# a34m42x register map
Vendor: ABOV Semiconductor Co., Ltd.; File version: 1.0
CPU: CM4 r0p1, little endian, MPU, FPU, VTOR, 4 interrupt priority bits
Registers are 32-bit, read-write, reset 0x0 unless marked. A register's access mark holds for its fields unless they carry their own. Offsets are from the block's base; [hi:lo] are bit positions; {n}, {i} and the like mark numbered series.

## FRT — Free Run Timer
Base 0x50000600
Same registers: FRT0 0x40000600, FRT1 0x40000700
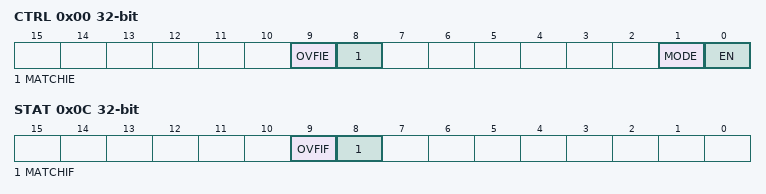
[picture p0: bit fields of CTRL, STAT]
0x00 CTRL — FRT n Control Register
  [9] OVFIE — Over Flow Interrupt Enable bit
    0=Disable (Interrupt Disable); 1=Enable (Interrupt Enable)
  [8] MATCHIE — Match Interrupt Enable Bit
    0=Disable (Interrupt Disable); 1=Enable (Interrupt Enable)
  [1] MODE — FRT Mode Selection Bit
    0=Free-Run_Timer; 1=Match_Timer
  [0] EN — FRT Enable Bit
    0=Disable (FRT Disable); 1=Enable (FRT Enable)
0x04 MCNT reset 0xFFFFFFFF — FRT n Match Counter Register
  [31:0] MCNT — Match Counter Bit
0x08 CNT — FRT n Counter Register
  [31:0] CNT — Counter Bit *only write '0x0'
0x0C STAT — FRT n Status Register
  [9] OVFIF — Overflow Interrupt Flag
  [8] MATCHIF — Match Interrupt Flag

## UART — Universal Asynchronous Receiver/Transmitter
Base 0x50008000
Same registers: UART0 0x40008000, UART1 0x40008100, UART2 0x40008200, UART3 0x40008300, UART4 0x40008400, UART5 0x40008500
0x00 RBR ro — UARTn Receive Data Buffer Register
  [7:0] RBR — Receive buffer
0x00 THR wo — UARTn Transmit Data Hold Register
  [7:0] THR — Transmit buffer
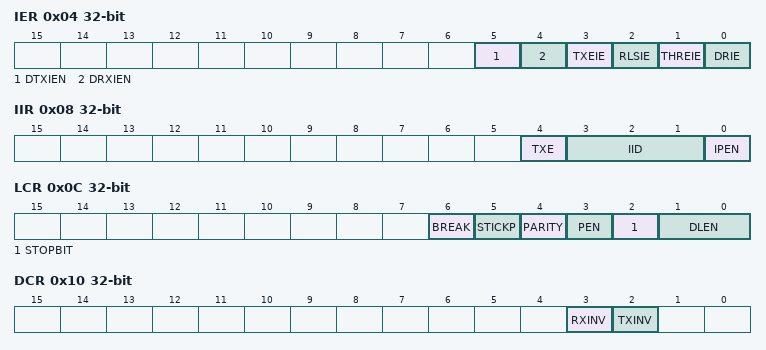
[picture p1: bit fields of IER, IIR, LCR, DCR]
0x04 IER — UARTn Interrupt Enable Register
  [5] DTXIEN — DMA Transmitter complete interrupt allow
  [4] DRXIEN — DMA Receiver over Interrupt allow
  [3] TXEIE — Transmit Empty Interrupt Enable bit
  [2] RLSIE — Receiver Line Status Interrupt Enable bit
  [1] THREIE — Transmit Holding Register Empty Interrupt Enable bit
  [0] DRIE — Data Receive Interrupt Enable bit
0x08 IIR ro — UARTn Interrupt ID Register
  [4] TXE — Transmit Complete Interrupt Source ID bit
  [3:1] IID — UARTn Interrupt ID bits. Note: The UARTn supports 3-priority interrupt generation and the interrupt source ID register shows one interrupt source which has highest priority among pending interrupts. The priority is defined as below. - Receive line status interrupt - Receive data ready interrupt and Character timeout interrupt - Transmit hold register empty interrupt
  [0] IPEN — Interrupt Pending bit
0x0C LCR — UARTn Line Control Register
  [6] BREAK — Transfer Break Control bit. The TXDn pin will be driven at low state in order to notice
  [5] STICKP — Force Parity bit. This bit is effective when the PEN bit is set to '1b'
  [4] PARITY — Parity Mode and Parity Stuck Selection bit
  [3] PEN — Parity Bit Transfer Enable bit
  [2] STOPBIT — Stop Bit Length Selection bit
  [1:0] DLEN — Data Length Selection bits
    {v}={v+5}bit data (v=0..3)
0x10 DCR — UARTn Data Control Register
  [3] RXINV — Rx Data Polarity selection
  [2] TXINV — Transmit Data Inversion Selection bit
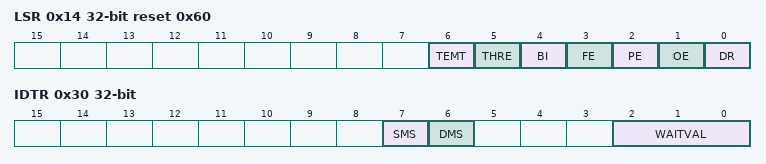
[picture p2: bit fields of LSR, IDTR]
0x14 LSR ro reset 0x60 — UARTn Line Status Register
  [6] TEMT — Transmit Empty bit
  [5] THRE — Transmit Holding Empty bit. Note: This bit will be set to '1b' when it starts transmit.
  [4] BI — Break Condition Indication bit
  [3] FE — Frame Error Indicator bit
  [2] PE — Parity Error Indicator bit
  [1] OE — Overrun Error Indicator bit
  [0] DR — Data Receive Indicator bit
0x20 BDR — UARTn Baud Rate Divisor Latch Register
  [15:0] BDR — Baud Rate Divider Latch Value. Baud rate = fUARTnCLK/(16 x BDR[15:0] x 2). Note: The UART block won't work if the BDR[15:0] == 0x0000.
0x24 BFR — UARTn Baud Rate Fractional Counter Value
  [7:0] BFR — Fraction Counter value. 0 = Disable fraction counter N = Fraction compensation mode is operating. Fraction counter is incremented by FCNT. FCNT = Float * 256 Note: 8-bit fractional counter will count up by FCNT value every (baud rate)/16 period and whenever fractional counter overflow is happen, the divisor value will increment by 1. So this period will be compensated. Then next period, the divisor value will return to original set value.
0x30 IDTR — UARTn Inter-frame Delay Time Register
  [7] SMS — Start Bit Multi Sampling Enable bit
  [6] DMS — Data Bit Multi sampling enable
  [2:0] WAITVAL — Wait Time Value. Dummy delay can be inserted between 2 Continuous Transmits. Wait Time = WAITVAL[2:0]/(Baud Rate)
